VERSION ""

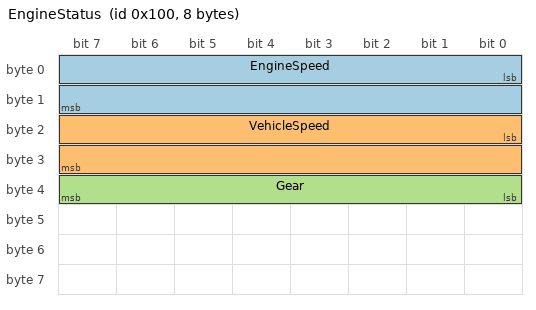
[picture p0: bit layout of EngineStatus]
BO_ 256 EngineStatus: 8 BCM
 SG_ EngineSpeed : 0|16@1+ (0.25,0) [0|8000] "rpm" ECU
 SG_ VehicleSpeed : 16|16@1+ (0.01,0) [0|250] "km/h" ECU
 SG_ Gear : 32|8@1+ (1,0) [0|8] "" ECU

BO_ 512 BCMStatus: 4 BCM
 SG_ DoorState : 0|4@1+ (1,0) [0|1] "" BCM
 SG_ LockState : 4|4@1+ (1,0) [0|1] "" BCM

CM_ BO_ 256 "Engine status broadcast message";
CM_ SG_ 256 EngineSpeed "Current engine RPM";
